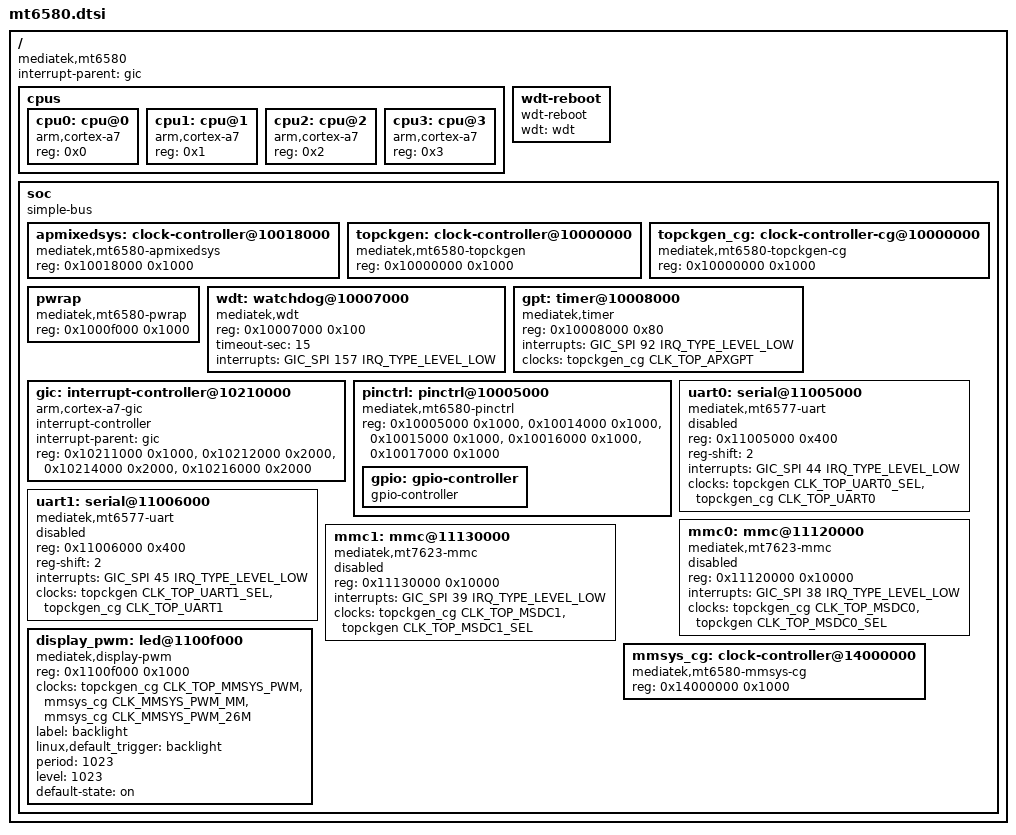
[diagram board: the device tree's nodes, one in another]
#include <dt-bindings/interrupt-controller/irq.h>
#include <dt-bindings/interrupt-controller/arm-gic.h>
#include <dt-bindings/phy/phy.h>
#include <dt-bindings/gpio/gpio.h>
#include <dt-bindings/clock/mt6580-clk.h>

/ {
  compatible = "mediatek,mt6580";
  #address-cells = <1>;
  #size-cells = <1>;
  interrupt-parent = <&gic>;

  cpus {
    #address-cells = <1>;
    #size-cells = <0>;

    cpu0: cpu@0 {
      compatible = "arm,cortex-a7";
      device_type = "cpu";
      reg = <0x0>;
    };

    cpu1: cpu@1 {
      compatible = "arm,cortex-a7";
      device_type = "cpu";
      reg = <0x1>;
    };
    
    cpu2: cpu@2 {
      compatible = "arm,cortex-a7";
      device_type = "cpu";
      reg = <0x2>;
    };
    
    cpu3: cpu@3 {
      compatible = "arm,cortex-a7";
      device_type = "cpu";
      reg = <0x3>;
    };
  };
  
  wdt-reboot {
    compatible = "wdt-reboot";
    wdt = <&wdt>;
    status = "okay";
  };

  soc {
    #address-cells = <1>;
    #size-cells = <1>;
    compatible = "simple-bus";
    ranges;

    apmixedsys: clock-controller@10018000 {
      compatible = "mediatek,mt6580-apmixedsys";
      reg = <0x10018000 0x1000>;
      #clock-cells = <1>;
    };

    topckgen: clock-controller@10000000 {
      compatible = "mediatek,mt6580-topckgen";
      reg = <0x10000000 0x1000>;
      #clock-cells = <1>;
    };

    topckgen_cg: clock-controller-cg@10000000 {
      compatible = "mediatek,mt6580-topckgen-cg";
      reg = <0x10000000 0x1000>;
      #clock-cells = <1>;
    };

    pwrap: pwrap {
      compatible = "mediatek,mt6580-pwrap";
      reg = <0x1000f000 0x1000>;
    };

    wdt: watchdog@10007000 {
      compatible = "mediatek,wdt";
      reg = <0x10007000 0x100>;
      timeout-sec = <15>;
      interrupts = <GIC_SPI 157 IRQ_TYPE_LEVEL_LOW>;
    };

    gpt: timer@10008000 {
      compatible = "mediatek,timer";
      reg = <0x10008000 0x80>;
      interrupts = <GIC_SPI 92 IRQ_TYPE_LEVEL_LOW>;
      clocks = <&topckgen_cg CLK_TOP_APXGPT>;
    };

    gic: interrupt-controller@10210000 {
      compatible = "arm,cortex-a7-gic";
      interrupt-controller;
      #interrupt-cells = <3>;
      interrupt-parent = <&gic>;
      reg = <0x10211000 0x1000>,
            <0x10212000 0x2000>,
            <0x10214000 0x2000>,
            <0x10216000 0x2000>;
    };

    pinctrl: pinctrl@10005000 {
      compatible = "mediatek,mt6580-pinctrl";
      reg = <0x10005000 0x1000>,
            <0x10014000 0x1000>,
            <0x10015000 0x1000>,
            <0x10016000 0x1000>,
            <0x10017000 0x1000>;
      reg-names = "gpio", "iocfg_t",
                  "iocfg_b", "iocfg_l", "iocfg_r";

      gpio: gpio-controller {
        gpio-controller;
        #gpio-cells = <2>;
      };
    };

    uart0: serial@11005000 {
      compatible = "mediatek,mt6577-uart";
      reg = <0x11005000 0x400>;
      reg-shift = <2>;
      interrupts = <GIC_SPI 44 IRQ_TYPE_LEVEL_LOW>;
      clocks =  <&topckgen CLK_TOP_UART0_SEL>,
                <&topckgen_cg CLK_TOP_UART0>;
      clock-names = "baud", "bus";
      status = "disabled";
    };

    uart1: serial@11006000 {
      compatible = "mediatek,mt6577-uart";
      reg = <0x11006000 0x400>;
      reg-shift = <2>;
      interrupts = <GIC_SPI 45 IRQ_TYPE_LEVEL_LOW>;
      clocks =  <&topckgen CLK_TOP_UART1_SEL>,
                <&topckgen_cg CLK_TOP_UART1>;
      clock-names = "baud", "bus";
      status = "disabled";
    };

    mmc0: mmc@11120000 {
      compatible = "mediatek,mt7623-mmc";
      reg = <0x11120000 0x10000>;
      interrupts = <GIC_SPI 38 IRQ_TYPE_LEVEL_LOW>;
      clocks = <&topckgen_cg CLK_TOP_MSDC0>,
               <&topckgen CLK_TOP_MSDC0_SEL>;
      clock-names = "source", "hclk";
      status = "disabled";
    };

    mmc1: mmc@11130000 {
      compatible = "mediatek,mt7623-mmc";
      reg = <0x11130000 0x10000>;
      interrupts = <GIC_SPI 39 IRQ_TYPE_LEVEL_LOW>;
      clocks = <&topckgen_cg CLK_TOP_MSDC1>,
               <&topckgen CLK_TOP_MSDC1_SEL>;
      clock-names = "source", "hclk";
      status = "disabled";
    };

    mmsys_cg: clock-controller@14000000 {
      compatible = "mediatek,mt6580-mmsys-cg";
      reg = <0x14000000 0x1000>;
      #clock-cells = <1>;
    };

    display_pwm: led@1100f000 {
      compatible = "mediatek,display-pwm";
      reg = <0x1100f000 0x1000>;
      clocks =  <&topckgen_cg CLK_TOP_MMSYS_PWM>,
                <&mmsys_cg CLK_MMSYS_PWM_MM>,
                <&mmsys_cg CLK_MMSYS_PWM_26M>;
      label = "backlight";
      linux,default_trigger = "backlight";
      period = <1023>;
      level = <1023>;
      default-state = "on";
    };
  };
};
